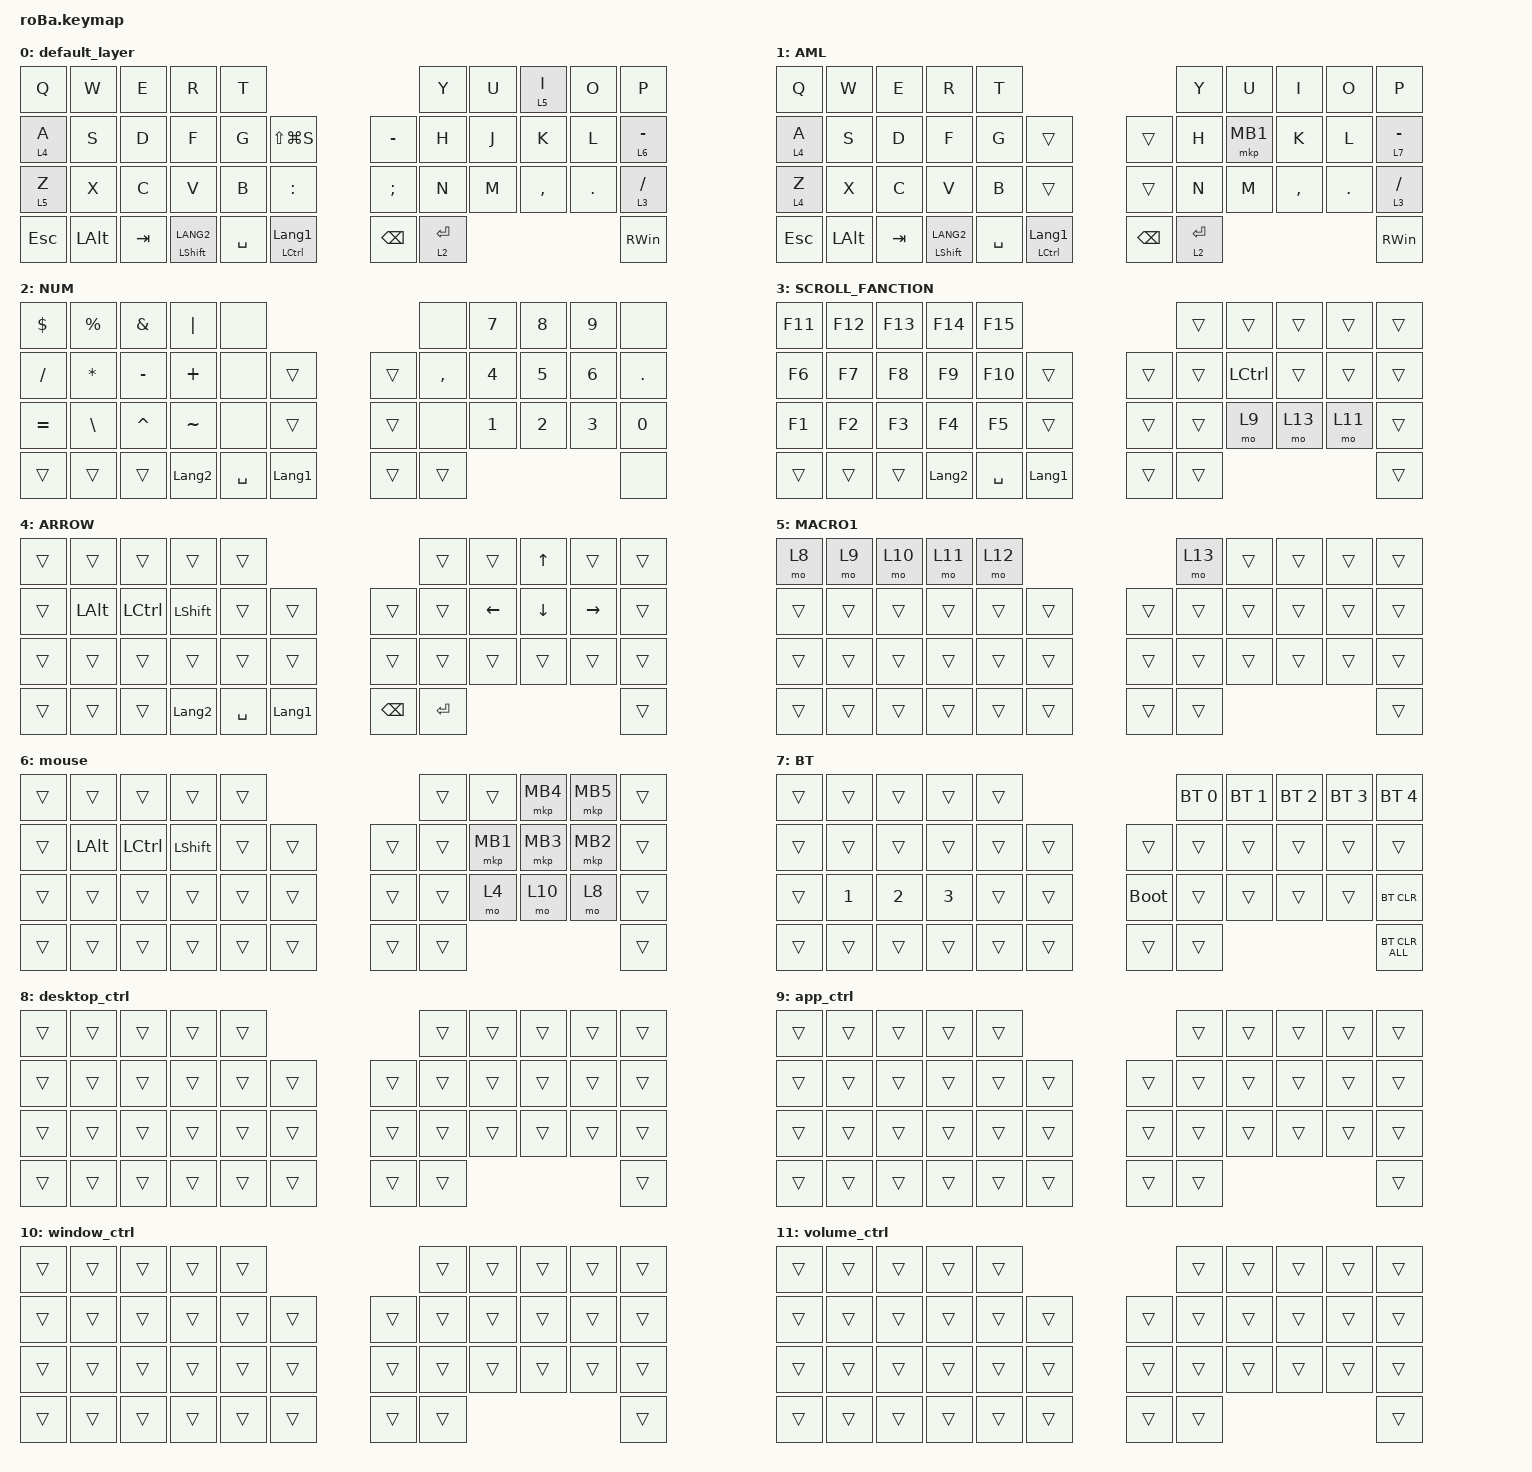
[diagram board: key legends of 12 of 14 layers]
#include <behaviors.dtsi>
#include <dt-bindings/zmk/bt.h>
#include <dt-bindings/zmk/keys.h>
#include <dt-bindings/zmk/pointing.h>

&mt {
    flavor = "balanced";
    tapping-term-ms = <180>;
    quick-tap-ms = <120>;
};

&lt {
    flavor = "balanced";
    tapping-term-ms = <180>;
    quick-tap-ms = <120>;
};

/*
 * Keyball QK_KB_21/22/23/26/27/28 compatible gesture layers.
 *
 * MACRO1 layer:
 *   Q -> KB21 Windows gesture
 *   W -> KB22 Alt-Tab gesture
 *   E -> KB23 Window gesture
 *   R -> KB26 Volume gesture
 *   T -> KB27 Arrow gesture
 *   Y -> KB28 Browser-tab gesture
 *
 * Hold the key, then move the trackball.
 */

&trackball {
    automouse-layer = <1>;
    scroll-layers = <3>;

    arrows {
        layers = <2>;
        bindings =
            <&kp RIGHT_ARROW>,
            <&kp LEFT_ARROW>,
            <&kp UP_ARROW>,
            <&kp DOWN_ARROW>;

        tick = <10>;
        wait-ms = <5>;
        tap-ms = <5>;
    };

    kb21_windows_gesture {
        layers = <8>;
        bindings =
            <&kp LC(LG(RIGHT_ARROW))>,
            // Right: Virtual desktop right,,,
            <&kp LC(LG(LEFT_ARROW))>,
            // Left: Virtual desktop left,,,
            <&kp LG(TAB)>,
            // Up: Task view,,,
            <&kp LG(D)>;

        // Down: Show desktop

        tick = <210>;
        wait-ms = <5>;
        tap-ms = <5>;
    };

    kb22_alt_tab_gesture {
        layers = <9>;
        bindings =
            <&kp LA(TAB)>,
            // Right: Next app,,,
            <&kp LA(LS(TAB))>,
            // Left: Previous app,,,
            <&kp LA(TAB)>,
            // Up: Alt+Tab,,,
            <&kp LA(F4)>;

        // Down: Alt+F4

        tick = <210>;
        wait-ms = <5>;
        tap-ms = <5>;
    };

    kb23_window_gesture {
        layers = <10>;
        bindings =
            <&kp LG(RIGHT_ARROW)>,
            // Right: Snap right,,,
            <&kp LG(LEFT_ARROW)>,
            // Left: Snap left,,,
            <&kp LG(UP_ARROW)>,
            // Up: Maximize,,,
            <&kp LG(DOWN_ARROW)>;

        // Down: Minimize / restore

        tick = <210>;
        wait-ms = <5>;
        tap-ms = <5>;
    };

    kb26_volume_gesture {
        layers = <11>;
        bindings =
            <&kp C_MUTE>,
            // Right: Mute,,,
            <&kp C_MUTE>,
            // Left: Mute,,,
            <&kp C_VOLUME_UP>,
            // Up: Volume up,,,
            <&kp C_VOLUME_DOWN>;

        // Down: Volume down

        tick = <210>;
        wait-ms = <5>;
        tap-ms = <5>;
    };

    kb27_arrow_gesture {
        layers = <12>;
        bindings =
            <&kp RIGHT_ARROW>,
            <&kp LEFT_ARROW>,
            <&kp UP_ARROW>,
            <&kp DOWN_ARROW>;

        tick = <500>;
        wait-ms = <5>;
        tap-ms = <5>;
    };

    kb28_browser_tab_gesture {
        layers = <13>;
        bindings =
            <&kp LC(TAB)>,
            // Right: Next tab,,,
            <&kp LC(LS(TAB))>,
            // Left: Previous tab,,,
            <&kp LC(T)>,
            // Up: New tab,,,
            <&kp LC(W)>;

        // Down: Close tab

        tick = <210>;
        wait-ms = <5>;
        tap-ms = <5>;
    };
};

/ {
    combos {
        compatible = "zmk,combos";
        timeout-ms = <85>;

        parentheses {
            bindings = <&paren_pair>;
            key-positions = <20 19>; // K + L
        };

        square_brackets {
            bindings = <&bracket_pair>;
            key-positions = <7 8>; // I + O
        };

        curly_brackets {
            bindings = <&brace_pair>;
            key-positions = <32 31>; // , + .
        };

        hash_tag {
            bindings = <&kp LS(N3)>; // #
            key-positions = <7 6>; // I + U
        };

        at_mark {
            bindings = <&kp LS(N2)>; // @
            key-positions = <19 18>; // J + K
        };

        exclamation {
            bindings = <&kp LS(N1)>; // !
            key-positions = <31 30>; // M + ,
        };

        semicolon {
            bindings = <&kp SEMI>;
            key-positions = <11 12>; // S + D
        };

        colon {
            bindings = <&kp COLON>;
            key-positions = <12 13>; // D + F
        };

        single_quote {
            bindings = <&kp SQT>;
            key-positions = <24 25>; // C + V
        };

        double_quotation {
            bindings = <&kp LS(SQT)>; // "
            key-positions = <24 23>; // C + X
        };

        yen_mark {
            bindings = <&kp BACKSLASH>;
            key-positions = <2 1>; // E + W
        };

        end {
            bindings = <&kp END>;
            key-positions = <0 1>;
        };

        home {
            bindings = <&kp HOME>;
            key-positions = <8 9>;
        };
    };

    macros {
        paren_pair: paren_pair {
            compatible = "zmk,behavior-macro";
            #binding-cells = <0>;
            bindings = <&kp LS(N9) &kp LS(N0)>;
        };

        bracket_pair: bracket_pair {
            compatible = "zmk,behavior-macro";
            #binding-cells = <0>;
            bindings = <&kp LEFT_BRACKET &kp RIGHT_BRACKET>;
        };

        brace_pair: brace_pair {
            compatible = "zmk,behavior-macro";
            #binding-cells = <0>;
            bindings = <&kp LS(LEFT_BRACKET) &kp LS(RIGHT_BRACKET)>;
        };
    };

    keymap {
        compatible = "zmk,keymap";

        default_layer {
            bindings = <
&kp Q       &kp W         &kp E    &kp R                 &kp T                                               &kp Y        &kp U  &lt 5 I    &kp O    &kp P
&lt 4 A     &kp S         &kp D    &kp F                 &kp G      &kp LS(LG(S))             &kp MINUS      &kp H        &kp J  &kp K      &kp L    &lt 6 MINUS
&lt 5 Z     &kp X         &kp C    &kp V                 &kp B      &kp COLON                 &kp SEMI       &kp N        &kp M  &kp COMMA  &kp DOT  &lt 3 SLASH
&kp ESCAPE  &kp LEFT_ALT  &kp TAB  &mt LEFT_SHIFT LANG2  &kp SPACE  &mt LCTRL LANGUAGE_1      &kp BACKSPACE  &lt 2 ENTER                             &kp RIGHT_WIN
            >;

            sensor-bindings = <&inc_dec_kp PG_UP PAGE_DOWN>;
        };

        AML {
            bindings = <
&kp Q    &kp W         &kp E    &kp R                 &kp T                                               &kp Y        &kp U     &kp I      &kp O       &kp P
&lt 4 A  &kp S         &kp D    &kp F                 &kp G      &trans                    &trans         &kp H        &mkp MB1  &kp K      &kp L       &lt 7 MINUS
&lt 4 Z  &kp X         &kp C    &kp V                 &kp B      &trans                    &trans         &kp N        &kp M     &kp COMMA  &kp PERIOD  &lt 3 SLASH
&kp ESC  &kp LEFT_ALT  &kp TAB  &mt LEFT_SHIFT LANG2  &kp SPACE  &mt LCTRL LANGUAGE_1      &kp BACKSPACE  &lt 2 ENTER                                   &kp RWIN
            >;
        };

        NUM {
            bindings = <
&kp DOLLAR  &kp PERCENT    &kp AMPERSAND  &kp PIPE        &none                                  &none      &kp N7        &kp N8        &kp N9        &none
&kp SLASH   &kp ASTERISK   &kp MINUS      &kp PLUS        &none      &trans              &trans  &kp COMMA  &kp NUMBER_4  &kp N5        &kp NUMBER_6  &kp PERIOD
&kp EQUAL   &kp BACKSLASH  &kp CARET      &kp TILDE       &none      &trans              &trans  &none      &kp NUMBER_1  &kp NUMBER_2  &kp NUMBER_3  &kp N0
&trans      &trans         &trans         &kp LANGUAGE_2  &kp SPACE  &kp LANGUAGE_1      &trans  &trans                                               &none
            >;
        };

        SCROLL_FANCTION {
            bindings = <
&kp F11  &kp F12  &kp F13  &kp F14         &kp F15                                &trans  &trans     &trans  &trans  &trans
&kp F6   &kp F7   &kp F8   &kp F9          &kp F10    &trans              &trans  &trans  &kp LCTRL  &trans  &trans  &trans
&kp F1   &kp F2   &kp F3   &kp F4          &kp F5     &trans              &trans  &trans  &mo 9      &mo 13  &mo 11  &trans
&trans   &trans   &trans   &kp LANGUAGE_2  &kp SPACE  &kp LANGUAGE_1      &trans  &trans                             &trans
            >;

            sensor-bindings = <&inc_dec_kp LC(PAGE_UP) LC(PAGE_DOWN)>;
        };

        ARROW {
            bindings = <
&trans  &trans        &trans     &trans          &trans                                        &trans     &trans    &kp UP_ARROW  &trans     &trans
&trans  &kp LEFT_ALT  &kp LCTRL  &kp LEFT_SHIFT  &trans     &trans              &trans         &trans     &kp LEFT  &kp DOWN      &kp RIGHT  &trans
&trans  &trans        &trans     &trans          &trans     &trans              &trans         &trans     &trans    &trans        &trans     &trans
&trans  &trans        &trans     &kp LANGUAGE_2  &kp SPACE  &kp LANGUAGE_1      &kp BACKSPACE  &kp ENTER                                     &trans
            >;
        };

        MACRO1 {
            bindings = <
&mo 8   &mo 9   &mo 10  &mo 11  &mo 12                      &mo 13  &trans  &trans  &trans  &trans
&trans  &trans  &trans  &trans  &trans  &trans      &trans  &trans  &trans  &trans  &trans  &trans
&trans  &trans  &trans  &trans  &trans  &trans      &trans  &trans  &trans  &trans  &trans  &trans
&trans  &trans  &trans  &trans  &trans  &trans      &trans  &trans                          &trans
            >;
        };

        mouse {
            bindings = <
&trans  &trans        &trans     &trans          &trans                      &trans  &trans    &mkp MB4  &mkp MB5  &trans
&trans  &kp LEFT_ALT  &kp LCTRL  &kp LEFT_SHIFT  &trans  &trans      &trans  &trans  &mkp MB1  &mkp MB3  &mkp MB2  &trans
&trans  &trans        &trans     &trans          &trans  &trans      &trans  &trans  &mo 4     &mo 10    &mo 8     &trans
&trans  &trans        &trans     &trans          &trans  &trans      &trans  &trans                                &trans
            >;
        };

        BT {
            bindings = <
&trans  &trans        &trans        &trans        &trans                           &bt BT_SEL 0  &bt BT_SEL 1  &bt BT_SEL 2  &bt BT_SEL 3  &bt BT_SEL 4
&trans  &trans        &trans        &trans        &trans  &trans      &trans       &trans        &trans        &trans        &trans        &trans
&trans  &kp NUMBER_1  &kp NUMBER_2  &kp NUMBER_3  &trans  &trans      &bootloader  &trans        &trans        &trans        &trans        &bt BT_CLR
&trans  &trans        &trans        &trans        &trans  &trans      &trans       &trans                                                  &bt BT_CLR_ALL
            >;
        };

        desktop_ctrl {
            bindings = <
&trans  &trans  &trans  &trans  &trans                      &trans  &trans  &trans  &trans  &trans
&trans  &trans  &trans  &trans  &trans  &trans      &trans  &trans  &trans  &trans  &trans  &trans
&trans  &trans  &trans  &trans  &trans  &trans      &trans  &trans  &trans  &trans  &trans  &trans
&trans  &trans  &trans  &trans  &trans  &trans      &trans  &trans                          &trans
            >;
        };

        app_ctrl {
            bindings = <
&trans  &trans  &trans  &trans  &trans                      &trans  &trans  &trans  &trans  &trans
&trans  &trans  &trans  &trans  &trans  &trans      &trans  &trans  &trans  &trans  &trans  &trans
&trans  &trans  &trans  &trans  &trans  &trans      &trans  &trans  &trans  &trans  &trans  &trans
&trans  &trans  &trans  &trans  &trans  &trans      &trans  &trans                          &trans
            >;
        };

        window_ctrl {
            bindings = <
&trans  &trans  &trans  &trans  &trans                      &trans  &trans  &trans  &trans  &trans
&trans  &trans  &trans  &trans  &trans  &trans      &trans  &trans  &trans  &trans  &trans  &trans
&trans  &trans  &trans  &trans  &trans  &trans      &trans  &trans  &trans  &trans  &trans  &trans
&trans  &trans  &trans  &trans  &trans  &trans      &trans  &trans                          &trans
            >;
        };

        volume_ctrl {
            bindings = <
&trans  &trans  &trans  &trans  &trans                      &trans  &trans  &trans  &trans  &trans
&trans  &trans  &trans  &trans  &trans  &trans      &trans  &trans  &trans  &trans  &trans  &trans
&trans  &trans  &trans  &trans  &trans  &trans      &trans  &trans  &trans  &trans  &trans  &trans
&trans  &trans  &trans  &trans  &trans  &trans      &trans  &trans                          &trans
            >;
        };

        arrow {
            bindings = <
&trans  &trans  &trans  &trans  &trans                      &trans  &trans  &trans  &trans  &trans
&trans  &trans  &trans  &trans  &trans  &trans      &trans  &trans  &trans  &trans  &trans  &trans
&trans  &trans  &trans  &trans  &trans  &trans      &trans  &trans  &trans  &trans  &trans  &trans
&trans  &trans  &trans  &trans  &trans  &trans      &trans  &trans                          &trans
            >;
        };

        tab_ie {
            bindings = <
&trans  &trans  &trans  &trans  &trans                      &trans  &trans  &trans  &trans  &trans
&trans  &trans  &trans  &trans  &trans  &trans      &trans  &trans  &trans  &trans  &trans  &trans
&trans  &trans  &trans  &trans  &trans  &trans      &trans  &trans  &trans  &trans  &trans  &trans
&trans  &trans  &trans  &trans  &trans  &trans      &trans  &trans                          &trans
            >;
        };
    };
};
